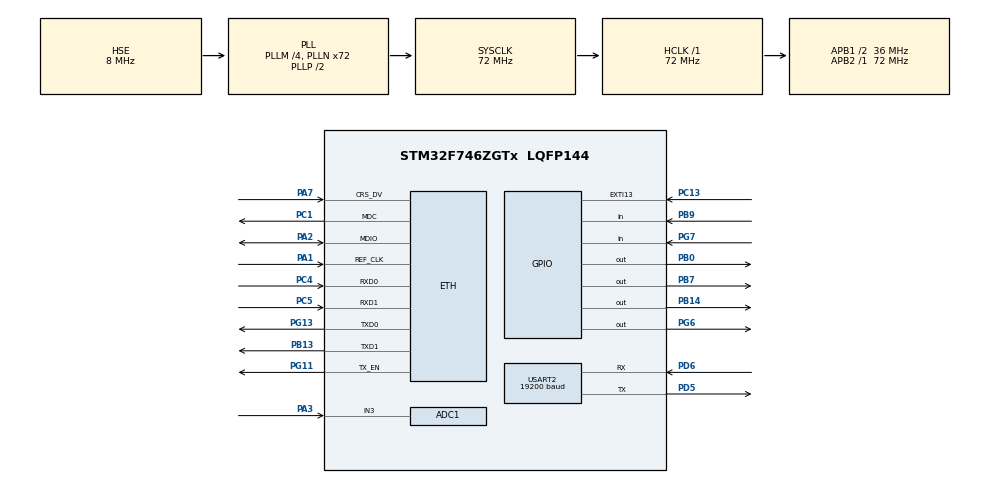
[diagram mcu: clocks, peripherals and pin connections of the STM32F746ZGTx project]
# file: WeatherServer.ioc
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ADC1.Channel-0\#ChannelRegularConversion=ADC_CHANNEL_3
ADC1.ContinuousConvMode=ENABLE
ADC1.DMAContinuousRequests=ENABLE
ADC1.NbrOfConversionFlag=1
ADC1.Rank-0\#ChannelRegularConversion=1
ADC1.SamplingTime-0\#ChannelRegularConversion=ADC_SAMPLETIME_3CYCLES
ADC1.master=1
Dma.ADC1.0.Direction=DMA_PERIPH_TO_MEMORY
Dma.ADC1.0.FIFOMode=DMA_FIFOMODE_DISABLE
Dma.ADC1.0.Instance=DMA2_Stream0
Dma.ADC1.0.MemDataAlignment=DMA_MDATAALIGN_HALFWORD
Dma.ADC1.0.MemInc=DMA_MINC_ENABLE
Dma.ADC1.0.Mode=DMA_CIRCULAR
Dma.ADC1.0.PeriphDataAlignment=DMA_PDATAALIGN_HALFWORD
Dma.ADC1.0.PeriphInc=DMA_PINC_DISABLE
Dma.ADC1.0.Priority=DMA_PRIORITY_LOW
Dma.Request0=ADC1
Dma.Request1=USART2_RX
Dma.USART2_RX.1.Direction=DMA_PERIPH_TO_MEMORY
Dma.USART2_RX.1.FIFOMode=DMA_FIFOMODE_DISABLE
Dma.USART2_RX.1.Instance=DMA1_Stream5
Dma.USART2_RX.1.MemDataAlignment=DMA_MDATAALIGN_BYTE
Dma.USART2_RX.1.MemInc=DMA_MINC_ENABLE
Dma.USART2_RX.1.Mode=DMA_CIRCULAR
Dma.USART2_RX.1.PeriphDataAlignment=DMA_PDATAALIGN_BYTE
Dma.USART2_RX.1.PeriphInc=DMA_PINC_DISABLE
Dma.USART2_RX.1.Priority=DMA_PRIORITY_LOW
ETH.MACAddr=02\:00\:00\:00\:00\:04
ETH.MediaInterface=HAL_ETH_RMII_MODE
ETH.PHY_Name=LAN8742A_PHY_ADDRESS
ETH.PHY_Value=0
ETH.PhyAddress=0
FREERTOS.BinarySemaphores01=OutBufferSem,Dynamic,NULL,
FREERTOS.Tasks01=defaultTask,0,128,StartDefaultTask,Default,NULL
FREERTOS.configUSE_NEWLIB_REENTRANT=1
FREERTOS.configUSE_PREEMPTION=1
LWIP.BSP.number=1
LWIP.HTTPD_USE_CUSTOM_FSDATA=1
LWIP.LWIP_HTTPD=1
LWIP.LWIP_HTTPD_CGI=1
LWIP.LWIP_HTTPD_CGI_SSI=0
LWIP.LWIP_HTTPD_MAX_REQUEST_URI_LEN=63
LWIP.LWIP_HTTPD_MAX_TAG_NAME_LEN=32
LWIP.LWIP_HTTPD_SSI=1
LWIP.Version=v2.1.2_Cube
LWIP0.BSP.STBoard=false
LWIP0.BSP.api=BSP_COMPONENT_DRIVER
LWIP0.BSP.component=LAN8742
LWIP0.BSP.instance=LAN8742
LWIP0.BSP.name=Driver_PHY
LWIP0.BSP.semaphore=S_LAN8742
LWIP0.BSP.solution=LAN8742
Mcu.Family=STM32F7
Mcu.Name=STM32F746ZGTx
Mcu.Package=LQFP144
NVIC.DMA1_Stream5_IRQn=true\:5\:0\:false\:false\:true\:true\:false\:true\:true
NVIC.DMA2_Stream0_IRQn=true\:5\:0\:false\:false\:true\:true\:false\:true\:true
NVIC.ETH_IRQn=true\:5\:0\:false\:false\:true\:true\:false\:true\:true
NVIC.PriorityGroup=NVIC_PRIORITYGROUP_4
NVIC.TIM1_UP_TIM10_IRQn=true\:0\:0\:false\:false\:true\:false\:false\:true\:true
NVIC.TimeBase=TIM1_UP_TIM10_IRQn
NVIC.TimeBaseIP=TIM1
NVIC.USART2_IRQn=true\:5\:0\:false\:false\:true\:true\:true\:true\:true
PA1.GPIO_Mode=GPIO_MODE_AF_PP
PA1.GPIO_PuPd=GPIO_NOPULL
PA1.GPIO_Speed=GPIO_SPEED_FREQ_VERY_HIGH
PA1.Mode=RMII
PA1.Signal=ETH_REF_CLK
PA10.GPIO_Mode=GPIO_MODE_AF_PP
PA10.GPIO_PuPd=GPIO_NOPULL
PA10.GPIO_Speed=GPIO_SPEED_FREQ_VERY_HIGH
PA10.Signal=USB_OTG_FS_ID
PA11.GPIO_Mode=GPIO_MODE_AF_PP
PA11.GPIO_PuPd=GPIO_NOPULL
PA11.GPIO_Speed=GPIO_SPEED_FREQ_VERY_HIGH
PA11.Signal=USB_OTG_FS_DM
PA12.GPIO_Mode=GPIO_MODE_AF_PP
PA12.GPIO_PuPd=GPIO_NOPULL
PA12.GPIO_Speed=GPIO_SPEED_FREQ_VERY_HIGH
PA12.Signal=USB_OTG_FS_DP
PA13.Mode=Serial_Wire
PA13.Signal=SYS_JTMS-SWDIO
PA14.Mode=Serial_Wire
PA14.Signal=SYS_JTCK-SWCLK
PA2.GPIO_Mode=GPIO_MODE_AF_PP
PA2.GPIO_PuPd=GPIO_NOPULL
PA2.GPIO_Speed=GPIO_SPEED_FREQ_VERY_HIGH
PA2.Mode=RMII
PA2.Signal=ETH_MDIO
PA3.Signal=ADCx_IN3
PA7.GPIO_Mode=GPIO_MODE_AF_PP
PA7.GPIO_PuPd=GPIO_NOPULL
PA7.GPIO_Speed=GPIO_SPEED_FREQ_VERY_HIGH
PA7.Mode=RMII
PA7.Signal=ETH_CRS_DV
PA8.GPIO_Mode=GPIO_MODE_AF_PP
PA8.GPIO_PuPd=GPIO_NOPULL
PA8.GPIO_Speed=GPIO_SPEED_FREQ_VERY_HIGH
PA8.Signal=USB_OTG_FS_SOF
PA9.GPIO_Mode=GPIO_MODE_INPUT
PA9.GPIO_PuPd=GPIO_NOPULL
PA9.Signal=USB_OTG_FS_VBUS
PB0.GPIO_ModeDefaultOutputPP=GPIO_MODE_OUTPUT_PP
PB0.GPIO_PuPd=GPIO_NOPULL
PB0.GPIO_Speed=GPIO_SPEED_FREQ_LOW
PB0.PinState=GPIO_PIN_RESET
PB0.Signal=GPIO_Output
PB13.GPIO_Mode=GPIO_MODE_AF_PP
PB13.GPIO_PuPd=GPIO_NOPULL
PB13.GPIO_Speed=GPIO_SPEED_FREQ_VERY_HIGH
PB13.Mode=RMII
PB13.Signal=ETH_TXD1
PB14.GPIO_ModeDefaultOutputPP=GPIO_MODE_OUTPUT_PP
PB14.GPIO_PuPd=GPIO_NOPULL
PB14.GPIO_Speed=GPIO_SPEED_FREQ_LOW
PB14.PinState=GPIO_PIN_RESET
PB14.Signal=GPIO_Output
PB3.Signal=SYS_JTDO-SWO
PB7.GPIO_ModeDefaultOutputPP=GPIO_MODE_OUTPUT_PP
PB7.GPIO_PuPd=GPIO_NOPULL
PB7.GPIO_Speed=GPIO_SPEED_FREQ_LOW
PB7.PinState=GPIO_PIN_RESET
PB7.Signal=GPIO_Output
PB9.GPIO_PuPd=GPIO_PULLUP
PB9.Signal=GPIO_Input
PC1.GPIO_Mode=GPIO_MODE_AF_PP
PC1.GPIO_PuPd=GPIO_NOPULL
PC1.GPIO_Speed=GPIO_SPEED_FREQ_VERY_HIGH
PC1.Mode=RMII
PC1.Signal=ETH_MDC
PC13.GPIO_ModeDefaultEXTI=GPIO_MODE_IT_RISING
PC13.GPIO_PuPd=GPIO_NOPULL
PC13.Signal=GPXTI13
PC14/OSC32_IN.Mode=LSE-External-Oscillator
PC14/OSC32_IN.Signal=RCC_OSC32_IN
PC15/OSC32_OUT.Mode=LSE-External-Oscillator
PC15/OSC32_OUT.Signal=RCC_OSC32_OUT
PC4.GPIO_Mode=GPIO_MODE_AF_PP
PC4.GPIO_PuPd=GPIO_NOPULL
PC4.GPIO_Speed=GPIO_SPEED_FREQ_VERY_HIGH
PC4.Mode=RMII
PC4.Signal=ETH_RXD0
PC5.GPIO_Mode=GPIO_MODE_AF_PP
PC5.GPIO_PuPd=GPIO_NOPULL
PC5.GPIO_Speed=GPIO_SPEED_FREQ_VERY_HIGH
PC5.Mode=RMII
PC5.Signal=ETH_RXD1
PD5.GPIO_ModeDefaultPP=GPIO_MODE_AF_PP
PD5.GPIO_PuPd=GPIO_NOPULL
PD5.GPIO_Speed=GPIO_SPEED_FREQ_VERY_HIGH
PD5.Mode=Asynchronous
PD5.Signal=USART2_TX
PD6.GPIO_ModeDefaultPP=GPIO_MODE_AF_PP
PD6.GPIO_PuPd=GPIO_NOPULL
PD6.GPIO_Speed=GPIO_SPEED_FREQ_VERY_HIGH
PD6.Mode=Asynchronous
PD6.Signal=USART2_RX
PD8.GPIO_ModeDefaultPP=GPIO_MODE_AF_PP
PD8.GPIO_PuPd=GPIO_NOPULL
PD8.GPIO_Speed=GPIO_SPEED_FREQ_VERY_HIGH
PD8.Signal=USART3_TX
PD9.GPIO_ModeDefaultPP=GPIO_MODE_AF_PP
PD9.GPIO_PuPd=GPIO_NOPULL
PD9.GPIO_Speed=GPIO_SPEED_FREQ_VERY_HIGH
PD9.Signal=USART3_RX
PG11.GPIO_Mode=GPIO_MODE_AF_PP
PG11.GPIO_PuPd=GPIO_NOPULL
PG11.GPIO_Speed=GPIO_SPEED_FREQ_VERY_HIGH
PG11.Mode=RMII
PG11.Signal=ETH_TX_EN
PG13.GPIO_Mode=GPIO_MODE_AF_PP
PG13.GPIO_PuPd=GPIO_NOPULL
PG13.GPIO_Speed=GPIO_SPEED_FREQ_VERY_HIGH
PG13.Mode=RMII
PG13.Signal=ETH_TXD0
PG6.GPIO_ModeDefaultOutputPP=GPIO_MODE_OUTPUT_PP
PG6.GPIO_PuPd=GPIO_NOPULL
PG6.GPIO_Speed=GPIO_SPEED_FREQ_LOW
PG6.PinState=GPIO_PIN_RESET
PG6.Signal=GPIO_Output
PG7.GPIO_Mode=GPIO_MODE_INPUT
PG7.GPIO_PuPd=GPIO_NOPULL
PG7.Signal=GPIO_Input
PH0/OSC_IN.Mode=HSE-External-Clock-Source
PH0/OSC_IN.Signal=RCC_OSC_IN
PH1/OSC_OUT.Mode=HSE-External-Clock-Source
PH1/OSC_OUT.Signal=RCC_OSC_OUT
ProjectManager.HeapSize=0x200
ProjectManager.StackSize=0x400
ProjectManager.TargetToolchain=STM32CubeIDE
RCC.48MHZClocksFreq_Value=24000000
RCC.AHBFreq_Value=72000000
RCC.APB1CLKDivider=RCC_HCLK_DIV2
RCC.APB1Freq_Value=36000000
RCC.APB1TimFreq_Value=72000000
RCC.APB2Freq_Value=72000000
RCC.APB2TimFreq_Value=72000000
RCC.CortexFreq_Value=72000000
RCC.HCLKFreq_Value=72000000
RCC.HSE_VALUE=8000000
RCC.HSI_VALUE=16000000
RCC.PLLM=4
RCC.PLLMUL=RCC_PLL_MUL9
RCC.PLLN=72
RCC.PLLQ=3
RCC.PLLSourceVirtual=RCC_PLLSOURCE_HSE
RCC.PRESCALERUSB=RCC_USBCLKSOURCE_PLL_DIV1_5
RCC.SYSCLKFreq_VALUE=72000000
RCC.SYSCLKSource=RCC_SYSCLKSOURCE_PLLCLK
RCC.SYSCLKSourceVirtual=RCC_SYSCLKSOURCE_PLLCLK
RCC.USBFreq_Value=48000000
RCC.VCOOutputFreq_Value=144000000
SH.ADCx_IN3.0=ADC1_IN3,IN3
USART2.BaudRate=19200
USART2.VirtualMode-Asynchronous=VM_ASYNC
VP_FREERTOS_VS_CMSIS_V1.Mode=CMSIS_V1
VP_LWIP_VS_Enabled.Mode=Enabled
VP_SYS_VS_tim1.Mode=TIM1
board=NUCLEO-F746ZG

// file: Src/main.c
/* USER CODE BEGIN Header */
/**
  ******************************************************************************
  * @file           : main.c
  * @brief          : Main program body
  ******************************************************************************
  * @attention
  *
  * <h2><center>&copy; Copyright (c) 2020 STMicroelectronics.
  * All rights reserved.</center></h2>
  *
  * This software component is licensed by ST under Ultimate Liberty license
  * SLA0044, the "License"; You may not use this file except in compliance with
  * the License. You may obtain a copy of the License at:
  *                             www.st.com/SLA0044
  *
  ******************************************************************************
  */
/* USER CODE END Header */
#include "main.h"
#include "cmsis_os.h"
#include "lwip.h"

/* USER CODE BEGIN Includes */

#include "WeatherServer.h"

/* USER CODE END Includes */

ADC_HandleTypeDef hadc1;
DMA_HandleTypeDef hdma_adc1;

UART_HandleTypeDef huart2;
DMA_HandleTypeDef hdma_usart2_rx;

osThreadId defaultTaskHandle;
osSemaphoreId OutBufferSemHandle;

void SystemClock_Config(void);
static void MX_GPIO_Init(void);
static void MX_DMA_Init(void);
static void MX_ADC1_Init(void);
static void MX_USART2_UART_Init(void);
void StartDefaultTask(void const * argument);

/* USER CODE BEGIN 0 */
// hack to make  link
__attribute__((weak)) void _close(void){}
__attribute__((weak)) void _lseek(void){}
__attribute__((weak)) void _read(void){}
__attribute__((weak)) void _write(void){}
__attribute__((weak)) void _sbrk(void){}
__attribute__((weak)) void _exit(int){while(1);}//
__attribute__((weak)) void _fstat(void){}
__attribute__((weak)) void _isatty(void){}
__attribute__((weak)) void _kill(void){}
__attribute__((weak)) void _getpid(void){}

/* USER CODE END 0 */

int main(void)
{

  /* MCU Configuration--------------------------------------------------------*/

  /* Reset of all peripherals, Initializes the Flash interface and the Systick. */
  HAL_Init();

  /* Configure the system clock */
  SystemClock_Config();

  /* USER CODE BEGIN SysInit */
  /* definition and creation of OutBufferSem */

  /* USER CODE END SysInit */

  /* Initialize all configured peripherals */
  MX_GPIO_Init();
  MX_DMA_Init();
  MX_ADC1_Init();
  MX_USART2_UART_Init();
  /* USER CODE BEGIN 2 */
  WeatherServerInit(&hadc1, &hdma_adc1,&huart2, &hdma_usart2_rx);
  /* USER CODE END 2 */

  /* Create the semaphores(s) */
  /* definition and creation of OutBufferSem */
  osSemaphoreDef(OutBufferSem);
  OutBufferSemHandle = osSemaphoreCreate(osSemaphore(OutBufferSem), 1);

  /* Create the thread(s) */
  /* definition and creation of defaultTask */
  osThreadDef(defaultTask, StartDefaultTask, osPriorityNormal, 0, 128);
  defaultTaskHandle = osThreadCreate(osThread(defaultTask), NULL);

  /* Start scheduler */
  osKernelStart();

  /* We should never get here as control is now taken by the scheduler */

  /* Infinite loop */
  while (1)
  {

  }
}

void SystemClock_Config(void)
{
  RCC_OscInitTypeDef RCC_OscInitStruct = {0};
  RCC_ClkInitTypeDef RCC_ClkInitStruct = {0};

  /** Configure LSE Drive Capability
  */
  HAL_PWR_EnableBkUpAccess();

  /** Configure the main internal regulator output voltage
  */
  __HAL_RCC_PWR_CLK_ENABLE();
  __HAL_PWR_VOLTAGESCALING_CONFIG(PWR_REGULATOR_VOLTAGE_SCALE3);

  /** Initializes the RCC Oscillators according to the specified parameters
  * in the RCC_OscInitTypeDef structure.
  */
  RCC_OscInitStruct.OscillatorType = RCC_OSCILLATORTYPE_HSE;
  RCC_OscInitStruct.HSEState = RCC_HSE_BYPASS;
  RCC_OscInitStruct.PLL.PLLState = RCC_PLL_ON;
  RCC_OscInitStruct.PLL.PLLSource = RCC_PLLSOURCE_HSE;
  RCC_OscInitStruct.PLL.PLLM = 4;
  RCC_OscInitStruct.PLL.PLLN = 72;
  RCC_OscInitStruct.PLL.PLLP = RCC_PLLP_DIV2;
  RCC_OscInitStruct.PLL.PLLQ = 3;
  if (HAL_RCC_OscConfig(&RCC_OscInitStruct) != HAL_OK)
  {
    Error_Handler();
  }

  /** Initializes the CPU, AHB and APB buses clocks
  */
  RCC_ClkInitStruct.ClockType = RCC_CLOCKTYPE_HCLK|RCC_CLOCKTYPE_SYSCLK
                              |RCC_CLOCKTYPE_PCLK1|RCC_CLOCKTYPE_PCLK2;
  RCC_ClkInitStruct.SYSCLKSource = RCC_SYSCLKSOURCE_PLLCLK;
  RCC_ClkInitStruct.AHBCLKDivider = RCC_SYSCLK_DIV1;
  RCC_ClkInitStruct.APB1CLKDivider = RCC_HCLK_DIV2;
  RCC_ClkInitStruct.APB2CLKDivider = RCC_HCLK_DIV1;

  if (HAL_RCC_ClockConfig(&RCC_ClkInitStruct, FLASH_LATENCY_2) != HAL_OK)
  {
    Error_Handler();
  }
}

static void MX_ADC1_Init(void)
{

  ADC_ChannelConfTypeDef sConfig = {0};

  /** Configure the global features of the ADC (Clock, Resolution, Data Alignment and number of conversion)
  */
  hadc1.Instance = ADC1;
  hadc1.Init.ClockPrescaler = ADC_CLOCK_SYNC_PCLK_DIV2;
  hadc1.Init.Resolution = ADC_RESOLUTION_12B;
  hadc1.Init.ScanConvMode = ADC_SCAN_DISABLE;
  hadc1.Init.ContinuousConvMode = ENABLE;
  hadc1.Init.DiscontinuousConvMode = DISABLE;
  hadc1.Init.ExternalTrigConvEdge = ADC_EXTERNALTRIGCONVEDGE_NONE;
  hadc1.Init.ExternalTrigConv = ADC_SOFTWARE_START;
  hadc1.Init.DataAlign = ADC_DATAALIGN_RIGHT;
  hadc1.Init.NbrOfConversion = 1;
  hadc1.Init.DMAContinuousRequests = ENABLE;
  hadc1.Init.EOCSelection = ADC_EOC_SINGLE_CONV;
  if (HAL_ADC_Init(&hadc1) != HAL_OK)
  {
    Error_Handler();
  }

  /** Configure for the selected ADC regular channel its corresponding rank in the sequencer and its sample time.
  */
  sConfig.Channel = ADC_CHANNEL_3;
  sConfig.Rank = ADC_REGULAR_RANK_1;
  sConfig.SamplingTime = ADC_SAMPLETIME_3CYCLES;
  if (HAL_ADC_ConfigChannel(&hadc1, &sConfig) != HAL_OK)
  {
    Error_Handler();
  }

}

static void MX_USART2_UART_Init(void)
{

  huart2.Instance = USART2;
  huart2.Init.BaudRate = 19200;
  huart2.Init.WordLength = UART_WORDLENGTH_8B;
  huart2.Init.StopBits = UART_STOPBITS_1;
  huart2.Init.Parity = UART_PARITY_NONE;
  huart2.Init.Mode = UART_MODE_TX_RX;
  huart2.Init.HwFlowCtl = UART_HWCONTROL_NONE;
  huart2.Init.OverSampling = UART_OVERSAMPLING_16;
  huart2.Init.OneBitSampling = UART_ONE_BIT_SAMPLE_DISABLE;
  huart2.AdvancedInit.AdvFeatureInit = UART_ADVFEATURE_NO_INIT;
  if (HAL_UART_Init(&huart2) != HAL_OK)
  {
    Error_Handler();
  }

}

static void MX_DMA_Init(void)
{

  /* DMA controller clock enable */
  __HAL_RCC_DMA2_CLK_ENABLE();
  __HAL_RCC_DMA1_CLK_ENABLE();

  /* DMA interrupt init */
  /* DMA1_Stream5_IRQn interrupt configuration */
  HAL_NVIC_SetPriority(DMA1_Stream5_IRQn, 5, 0);
  HAL_NVIC_EnableIRQ(DMA1_Stream5_IRQn);
  /* DMA2_Stream0_IRQn interrupt configuration */
  HAL_NVIC_SetPriority(DMA2_Stream0_IRQn, 5, 0);
  HAL_NVIC_EnableIRQ(DMA2_Stream0_IRQn);

}

static void MX_GPIO_Init(void)
{
  GPIO_InitTypeDef GPIO_InitStruct = {0};

  /* GPIO Ports Clock Enable */
  __HAL_RCC_GPIOC_CLK_ENABLE();
  __HAL_RCC_GPIOH_CLK_ENABLE();
  __HAL_RCC_GPIOA_CLK_ENABLE();
  __HAL_RCC_GPIOB_CLK_ENABLE();
  __HAL_RCC_GPIOD_CLK_ENABLE();
  __HAL_RCC_GPIOG_CLK_ENABLE();

  /*Configure GPIO pin Output Level */
  HAL_GPIO_WritePin(GPIOB, GPIO_PIN_0|GPIO_PIN_14|GPIO_PIN_7, GPIO_PIN_RESET);

  /*Configure GPIO pin Output Level */
  HAL_GPIO_WritePin(GPIOG, GPIO_PIN_6, GPIO_PIN_RESET);

  /*Configure GPIO pin : PC13 */
  GPIO_InitStruct.Pin = GPIO_PIN_13;
  GPIO_InitStruct.Mode = GPIO_MODE_IT_RISING;
  GPIO_InitStruct.Pull = GPIO_NOPULL;
  HAL_GPIO_Init(GPIOC, &GPIO_InitStruct);

  /*Configure GPIO pins : PB0 PB14 PB7 */
  GPIO_InitStruct.Pin = GPIO_PIN_0|GPIO_PIN_14|GPIO_PIN_7;
  GPIO_InitStruct.Mode = GPIO_MODE_OUTPUT_PP;
  GPIO_InitStruct.Pull = GPIO_NOPULL;
  GPIO_InitStruct.Speed = GPIO_SPEED_FREQ_LOW;
  HAL_GPIO_Init(GPIOB, &GPIO_InitStruct);

  /*Configure GPIO pins : PD8 PD9 */
  GPIO_InitStruct.Pin = GPIO_PIN_8|GPIO_PIN_9;
  GPIO_InitStruct.Mode = GPIO_MODE_AF_PP;
  GPIO_InitStruct.Pull = GPIO_NOPULL;
  GPIO_InitStruct.Speed = GPIO_SPEED_FREQ_VERY_HIGH;
  GPIO_InitStruct.Alternate = GPIO_AF7_USART3;
  HAL_GPIO_Init(GPIOD, &GPIO_InitStruct);

  /*Configure GPIO pin : PG6 */
  GPIO_InitStruct.Pin = GPIO_PIN_6;
  GPIO_InitStruct.Mode = GPIO_MODE_OUTPUT_PP;
  GPIO_InitStruct.Pull = GPIO_NOPULL;
  GPIO_InitStruct.Speed = GPIO_SPEED_FREQ_LOW;
  HAL_GPIO_Init(GPIOG, &GPIO_InitStruct);

  /*Configure GPIO pin : PG7 */
  GPIO_InitStruct.Pin = GPIO_PIN_7;
  GPIO_InitStruct.Mode = GPIO_MODE_INPUT;
  GPIO_InitStruct.Pull = GPIO_NOPULL;
  HAL_GPIO_Init(GPIOG, &GPIO_InitStruct);

  /*Configure GPIO pins : PA8 PA10 PA11 PA12 */
  GPIO_InitStruct.Pin = GPIO_PIN_8|GPIO_PIN_10|GPIO_PIN_11|GPIO_PIN_12;
  GPIO_InitStruct.Mode = GPIO_MODE_AF_PP;
  GPIO_InitStruct.Pull = GPIO_NOPULL;
  GPIO_InitStruct.Speed = GPIO_SPEED_FREQ_VERY_HIGH;
  GPIO_InitStruct.Alternate = GPIO_AF10_OTG_FS;
  HAL_GPIO_Init(GPIOA, &GPIO_InitStruct);

  /*Configure GPIO pin : PA9 */
  GPIO_InitStruct.Pin = GPIO_PIN_9;
  GPIO_InitStruct.Mode = GPIO_MODE_INPUT;
  GPIO_InitStruct.Pull = GPIO_NOPULL;
  HAL_GPIO_Init(GPIOA, &GPIO_InitStruct);

  /*Configure GPIO pin : PB9 */
  GPIO_InitStruct.Pin = GPIO_PIN_9;
  GPIO_InitStruct.Mode = GPIO_MODE_INPUT;
  GPIO_InitStruct.Pull = GPIO_PULLUP;
  HAL_GPIO_Init(GPIOB, &GPIO_InitStruct);

}

void StartDefaultTask(void const * argument)
{
  /* init code for LWIP */
  MX_LWIP_Init();
  /* USER CODE BEGIN 5 */
	WeatherServerDefaultTask();

  /* USER CODE END 5 */
}

void HAL_TIM_PeriodElapsedCallback(TIM_HandleTypeDef *htim)
{
  if (htim->Instance == TIM1)
  {
    HAL_IncTick();
  }
}

void Error_Handler(void)
{
}
